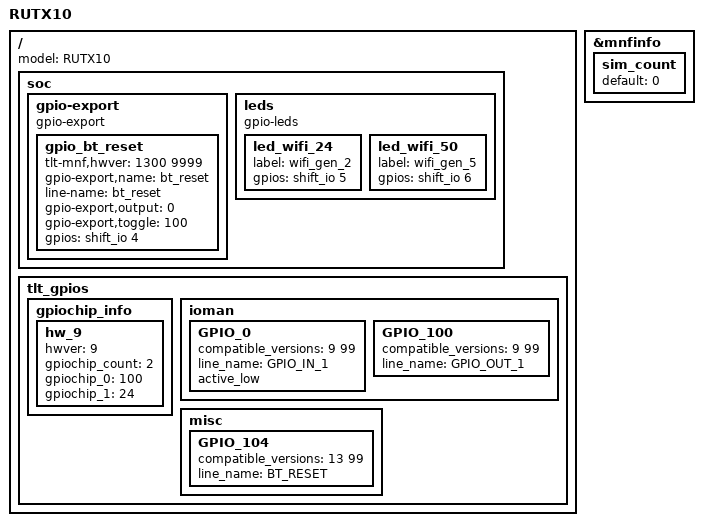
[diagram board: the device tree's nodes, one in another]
#include "qcom-ipq4018-rutx-shiftreg.dtsi"

/ {
	model = "RUTX10";

	soc {
		gpio-export {
			compatible = "gpio-export";
			#size-cells = <0>;

			gpio_bt_reset {
				tlt-mnf,hwver = <1300 9999>;
				gpio-export,name = "bt_reset";
				line-name = "bt_reset";
				gpio-export,output = <0>;
				gpio-export,toggle = <100>; // ms
				gpios = <&shift_io 4 GPIO_ACTIVE_HIGH>;
			};
		};

		leds {
			compatible = "gpio-leds";

			led_wifi_24 {
				label = "wifi_gen_2";
				gpios = <&shift_io 5 GPIO_ACTIVE_HIGH>;
			};

			led_wifi_50 {
				label = "wifi_gen_5";
				gpios = <&shift_io 6 GPIO_ACTIVE_HIGH>;
			};
		};
	};

	tlt_gpios { // Modify according to wiki page "DTS syntax with Libgpiod changes"
		gpiochip_info {
			hw_9 {
				hwver = <9>;
				gpiochip_count = <2>;

				gpiochip_0 = <100>; // Built-in
				gpiochip_1 = <24>;  // Shift Register
			};
		};

		ioman {
			GPIO_0 {
				compatible_versions = <9 99>;
				line_name = "GPIO_IN_1";
				active_low;
			};
			GPIO_100 {
				compatible_versions = <9 99>;
				line_name = "GPIO_OUT_1";
			};
		};

		misc {
			GPIO_104 {
				compatible_versions = <13 99>;
				line_name = "BT_RESET";
			};
		};
	};
};

&mnfinfo {
	/delete-node/ simpin1;
	/delete-node/ simpin2;

	sim_count {
		default =  "0";
	};
};
